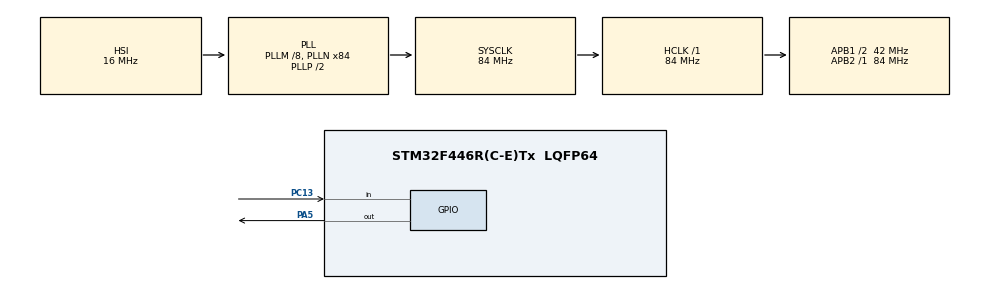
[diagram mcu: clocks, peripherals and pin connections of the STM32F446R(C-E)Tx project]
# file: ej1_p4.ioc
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Mcu.Family=STM32F4
Mcu.Name=STM32F446R(C-E)Tx
Mcu.Package=LQFP64
NVIC.PriorityGroup=NVIC_PRIORITYGROUP_4
PA13.Mode=Serial_Wire
PA13.Signal=SYS_JTMS-SWDIO
PA14.Mode=Serial_Wire
PA14.Signal=SYS_JTCK-SWCLK
PA5.Signal=GPIO_Output
PC13.GPIO_PuPd=GPIO_NOPULL
PC13.Signal=GPIO_Input
PC14-OSC32_IN.Mode=LSE-External-Oscillator
PC14-OSC32_IN.Signal=RCC_OSC32_IN
PC15-OSC32_OUT.Mode=LSE-External-Oscillator
PC15-OSC32_OUT.Signal=RCC_OSC32_OUT
PH0-OSC_IN.Mode=HSE-External-Oscillator
PH0-OSC_IN.Signal=RCC_OSC_IN
PH1-OSC_OUT.Mode=HSE-External-Oscillator
PH1-OSC_OUT.Signal=RCC_OSC_OUT
ProjectManager.HeapSize=0x200
ProjectManager.StackSize=0x400
ProjectManager.TargetToolchain=STM32CubeIDE
RCC.AHBFreq_Value=84000000
RCC.APB1CLKDivider=RCC_HCLK_DIV2
RCC.APB1Freq_Value=42000000
RCC.APB1TimFreq_Value=84000000
RCC.APB2Freq_Value=84000000
RCC.APB2TimFreq_Value=84000000
RCC.CortexFreq_Value=84000000
RCC.HCLKFreq_Value=84000000
RCC.PLLM=8
RCC.PLLN=84
RCC.SYSCLKFreq_VALUE=84000000
RCC.SYSCLKSource=RCC_SYSCLKSOURCE_PLLCLK
RCC.USBFreq_Value=84000000
RCC.VCOOutputFreq_Value=168000000
board=custom

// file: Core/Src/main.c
/* USER CODE BEGIN Header */
/**
  ******************************************************************************
  * @file           : main.c
  * @brief          : Main program body
  ******************************************************************************
  * @attention
  *
  * Copyright (c) 2025 STMicroelectronics.
  * All rights reserved.
  *
  * This software is licensed under terms that can be found in the LICENSE file
  * in the root directory of this software component.
  * If no LICENSE file comes with this software, it is provided AS-IS.
  *
  ******************************************************************************
  */
/* USER CODE END Header */
#include "main.h"

/* USER CODE BEGIN PTD */
typedef enum{
	BUTTON_UP,
	BUTTON_FALLING,
	BUTTON_DOWN,
	BUTTON_RAISING,
} debounceState_t;

/* USER CODE END PTD */

/* USER CODE BEGIN PM */
const tick_t no_noise=40;
/* USER CODE END PM */

/* USER CODE BEGIN PV */
debounceState_t state;
delay_t NB_delay;

/* USER CODE END PV */

void SystemClock_Config(void);
static void MX_GPIO_Init(void);
/* USER CODE BEGIN PFP */

void debounceFSM_init();			// debe cargar el estado inicial
void debounceFSM_update();			// debe leer las entradas, resolver la lógica de
									// transición de estados y actualizar las salidas
void buttonPressed();				// debe encender el LED
void buttonReleased();				// debe apagar el LED

/* USER CODE END PFP */

int main(void)
{

  /* MCU Configuration--------------------------------------------------------*/

  /* Reset of all peripherals, Initializes the Flash interface and the Systick. */
  HAL_Init();

  /* Configure the system clock */
  SystemClock_Config();

  /* Initialize all configured peripherals */
  MX_GPIO_Init();
  /* USER CODE BEGIN 2 */

  debounceFSM_init();

  /* USER CODE END 2 */

  /* Infinite loop */
  while (1)
  {

    /* USER CODE BEGIN 3 */

	  debounceFSM_update();
	  HAL_Delay(1);

  }
  /* USER CODE END 3 */
}

void SystemClock_Config(void)
{
  RCC_OscInitTypeDef RCC_OscInitStruct = {0};
  RCC_ClkInitTypeDef RCC_ClkInitStruct = {0};

  /** Configure the main internal regulator output voltage
  */
  __HAL_RCC_PWR_CLK_ENABLE();
  __HAL_PWR_VOLTAGESCALING_CONFIG(PWR_REGULATOR_VOLTAGE_SCALE3);

  /** Initializes the RCC Oscillators according to the specified parameters
  * in the RCC_OscInitTypeDef structure.
  */
  RCC_OscInitStruct.OscillatorType = RCC_OSCILLATORTYPE_HSI;
  RCC_OscInitStruct.HSIState = RCC_HSI_ON;
  RCC_OscInitStruct.HSICalibrationValue = RCC_HSICALIBRATION_DEFAULT;
  RCC_OscInitStruct.PLL.PLLState = RCC_PLL_ON;
  RCC_OscInitStruct.PLL.PLLSource = RCC_PLLSOURCE_HSI;
  RCC_OscInitStruct.PLL.PLLM = 8;
  RCC_OscInitStruct.PLL.PLLN = 84;
  RCC_OscInitStruct.PLL.PLLP = RCC_PLLP_DIV2;
  RCC_OscInitStruct.PLL.PLLQ = 2;
  RCC_OscInitStruct.PLL.PLLR = 2;
  if (HAL_RCC_OscConfig(&RCC_OscInitStruct) != HAL_OK)
  {
    Error_Handler();
  }

  /** Initializes the CPU, AHB and APB buses clocks
  */
  RCC_ClkInitStruct.ClockType = RCC_CLOCKTYPE_HCLK|RCC_CLOCKTYPE_SYSCLK
                              |RCC_CLOCKTYPE_PCLK1|RCC_CLOCKTYPE_PCLK2;
  RCC_ClkInitStruct.SYSCLKSource = RCC_SYSCLKSOURCE_PLLCLK;
  RCC_ClkInitStruct.AHBCLKDivider = RCC_SYSCLK_DIV1;
  RCC_ClkInitStruct.APB1CLKDivider = RCC_HCLK_DIV2;
  RCC_ClkInitStruct.APB2CLKDivider = RCC_HCLK_DIV1;

  if (HAL_RCC_ClockConfig(&RCC_ClkInitStruct, FLASH_LATENCY_2) != HAL_OK)
  {
    Error_Handler();
  }
}

static void MX_GPIO_Init(void)
{
  GPIO_InitTypeDef GPIO_InitStruct = {0};

  /* GPIO Ports Clock Enable */
  __HAL_RCC_GPIOC_CLK_ENABLE();
  __HAL_RCC_GPIOH_CLK_ENABLE();
  __HAL_RCC_GPIOA_CLK_ENABLE();

  /*Configure GPIO pin Output Level */
  HAL_GPIO_WritePin(GPIOA, GPIO_PIN_5, GPIO_PIN_RESET);

  /*Configure GPIO pin : PC13 */
  GPIO_InitStruct.Pin = GPIO_PIN_13;
  GPIO_InitStruct.Mode = GPIO_MODE_INPUT;
  GPIO_InitStruct.Pull = GPIO_NOPULL;
  HAL_GPIO_Init(GPIOC, &GPIO_InitStruct);

  /*Configure GPIO pin : PA5 */
  GPIO_InitStruct.Pin = GPIO_PIN_5;
  GPIO_InitStruct.Mode = GPIO_MODE_OUTPUT_PP;
  GPIO_InitStruct.Pull = GPIO_NOPULL;
  GPIO_InitStruct.Speed = GPIO_SPEED_FREQ_LOW;
  HAL_GPIO_Init(GPIOA, &GPIO_InitStruct);

}

/* USER CODE BEGIN 4 */

void debounceFSM_init(){
	state=BUTTON_UP;				//Inicializacion primer estado
}

void debounceFSM_update(){
	uint32_t Button_state=HAL_GPIO_ReadPin(B1_GPIO_Port, B1_Pin);

	switch(state){
		case BUTTON_UP:
			if(Button_state==GPIO_PIN_RESET){
				delayInit(&NB_delay,no_noise);
				state=BUTTON_FALLING;
			}
			break;

		case BUTTON_DOWN:
			if(Button_state==GPIO_PIN_SET){
				delayInit(&NB_delay,no_noise);
				state=BUTTON_RAISING;
			}
			break;

		case BUTTON_FALLING:
			if(!delayRead(&NB_delay)){
				buttonPressed();
				state=BUTTON_DOWN;
			}
			break;

		case BUTTON_RAISING:
			if(!delayRead(&NB_delay)){
				buttonReleased();
				state=BUTTON_UP;
			}
			break;
		default:
			break;
	}
}

void buttonPressed(){
	HAL_GPIO_WritePin(GPIOA, GPIO_PIN_5, 1);
}
void buttonReleased(){
	HAL_GPIO_WritePin(GPIOA, GPIO_PIN_5, 0);
}

/* USER CODE END 4 */

void Error_Handler(void)
{
  __disable_irq();
  while (1)
  {
  }
}
